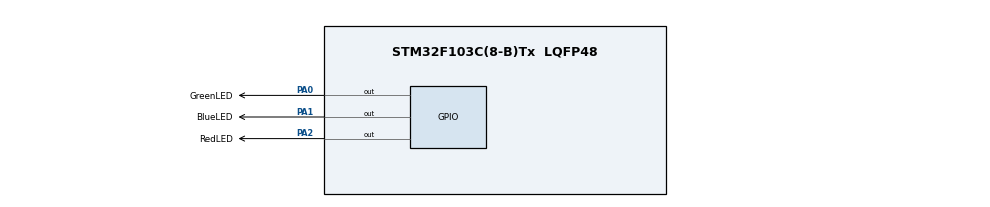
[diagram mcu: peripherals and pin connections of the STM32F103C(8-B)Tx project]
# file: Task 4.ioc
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FREERTOS.Tasks01=defaultTask,0,128,StartDefaultTask,Default,NULL,Dynamic,NULL,NULL;GreendLedFlash,-3,128,GreenLedTask,Default,NULL,Dynamic,NULL,NULL;RedLedFlash,0,128,RedLedTask,Default,NULL,Dynamic,NULL,NULL
FREERTOS.configUSE_NEWLIB_REENTRANT=1
Mcu.Family=STM32F1
Mcu.Name=STM32F103C(8-B)Tx
Mcu.Package=LQFP48
NVIC.PriorityGroup=NVIC_PRIORITYGROUP_4
NVIC.TIM4_IRQn=true\:15\:0\:false\:false\:true\:false\:false\:true\:true
NVIC.TimeBase=TIM4_IRQn
NVIC.TimeBaseIP=TIM4
PA0-WKUP.GPIO_Label=GreenLED
PA0-WKUP.Signal=GPIO_Output
PA1.GPIO_Label=BlueLED
PA1.Signal=GPIO_Output
PA13.Mode=Serial_Wire
PA13.Signal=SYS_JTMS-SWDIO
PA14.Mode=Serial_Wire
PA14.Signal=SYS_JTCK-SWCLK
PA2.GPIO_Label=RedLED
PA2.Signal=GPIO_Output
ProjectManager.HeapSize=0x200
ProjectManager.StackSize=0x400
ProjectManager.TargetToolchain=STM32CubeIDE
RCC.APB1Freq_Value=8000000
RCC.APB2Freq_Value=8000000
VP_FREERTOS_VS_CMSIS_V1.Mode=CMSIS_V1
VP_SYS_VS_tim4.Mode=TIM4
board=custom

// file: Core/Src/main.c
/* USER CODE BEGIN Header */
/**
  ******************************************************************************
  * @file           : main.c
  * @brief          : Main program body
  ******************************************************************************
  * @attention
  *
  * Copyright (c) 2024 STMicroelectronics.
  * All rights reserved.
  *
  * This software is licensed under terms that can be found in the LICENSE file
  * in the root directory of this software component.
  * If no LICENSE file comes with this software, it is provided AS-IS.
  *
  ******************************************************************************
  */
/* USER CODE END Header */
#include "main.h"
#include "cmsis_os.h"

/* USER CODE BEGIN PM */
volatile uint8_t startFlag = 1;
/* USER CODE END PM */

osThreadId defaultTaskHandle;
osThreadId GreendLedFlashHandle;
osThreadId RedLedFlashHandle;

void SystemClock_Config(void);
static void MX_GPIO_Init(void);
void StartDefaultTask(void const * argument);
void GreenLedTask(void const * argument);
void RedLedTask(void const * argument);

int main(void)
{

  /* MCU Configuration--------------------------------------------------------*/

  /* Reset of all peripherals, Initializes the Flash interface and the Systick. */
  HAL_Init();

  /* Configure the system clock */
  SystemClock_Config();

  /* Initialize all configured peripherals */
  MX_GPIO_Init();

  /* Create the thread(s) */
  /* definition and creation of defaultTask */
  osThreadDef(defaultTask, StartDefaultTask, osPriorityNormal, 0, 128);
  defaultTaskHandle = osThreadCreate(osThread(defaultTask), NULL);

  /* definition and creation of GreendLedFlash */
  osThreadDef(GreendLedFlash, GreenLedTask, osPriorityIdle, 0, 128);
  GreendLedFlashHandle = osThreadCreate(osThread(GreendLedFlash), NULL);

  /* definition and creation of RedLedFlash */
  osThreadDef(RedLedFlash, RedLedTask, osPriorityNormal, 0, 128);
  RedLedFlashHandle = osThreadCreate(osThread(RedLedFlash), NULL);

  /* Start scheduler */
  osKernelStart();
  /* We should never get here as control is now taken by the scheduler */
  /* Infinite loop */
  while (1)
  {

  }
}

void SystemClock_Config(void)
{
  RCC_OscInitTypeDef RCC_OscInitStruct = {0};
  RCC_ClkInitTypeDef RCC_ClkInitStruct = {0};

  /** Initializes the RCC Oscillators according to the specified parameters
  * in the RCC_OscInitTypeDef structure.
  */
  RCC_OscInitStruct.OscillatorType = RCC_OSCILLATORTYPE_HSI;
  RCC_OscInitStruct.HSIState = RCC_HSI_ON;
  RCC_OscInitStruct.HSICalibrationValue = RCC_HSICALIBRATION_DEFAULT;
  RCC_OscInitStruct.PLL.PLLState = RCC_PLL_NONE;
  if (HAL_RCC_OscConfig(&RCC_OscInitStruct) != HAL_OK)
  {
    Error_Handler();
  }

  /** Initializes the CPU, AHB and APB buses clocks
  */
  RCC_ClkInitStruct.ClockType = RCC_CLOCKTYPE_HCLK|RCC_CLOCKTYPE_SYSCLK
                              |RCC_CLOCKTYPE_PCLK1|RCC_CLOCKTYPE_PCLK2;
  RCC_ClkInitStruct.SYSCLKSource = RCC_SYSCLKSOURCE_HSI;
  RCC_ClkInitStruct.AHBCLKDivider = RCC_SYSCLK_DIV1;
  RCC_ClkInitStruct.APB1CLKDivider = RCC_HCLK_DIV1;
  RCC_ClkInitStruct.APB2CLKDivider = RCC_HCLK_DIV1;

  if (HAL_RCC_ClockConfig(&RCC_ClkInitStruct, FLASH_LATENCY_0) != HAL_OK)
  {
    Error_Handler();
  }
}

static void MX_GPIO_Init(void)
{
  GPIO_InitTypeDef GPIO_InitStruct = {0};

  /* GPIO Ports Clock Enable */
  __HAL_RCC_GPIOA_CLK_ENABLE();

  /*Configure GPIO pin Output Level */
  HAL_GPIO_WritePin(GPIOA, GreenLED_Pin|BlueLED_Pin|RedLED_Pin, GPIO_PIN_RESET);

  /*Configure GPIO pins : GreenLED_Pin BlueLED_Pin RedLED_Pin */
  GPIO_InitStruct.Pin = GreenLED_Pin|BlueLED_Pin|RedLED_Pin;
  GPIO_InitStruct.Mode = GPIO_MODE_OUTPUT_PP;
  GPIO_InitStruct.Pull = GPIO_NOPULL;
  GPIO_InitStruct.Speed = GPIO_SPEED_FREQ_LOW;
  HAL_GPIO_Init(GPIOA, &GPIO_InitStruct);

}

/* USER CODE BEGIN 4 */
void accessSharedData(void)
{
  if (startFlag == 1)
  {
    startFlag = 0;
  }
  else
  {
    HAL_GPIO_WritePin(GPIOA, GPIO_PIN_1, GPIO_PIN_SET);
  }
  osDelay(500);

  startFlag = 1;
  HAL_GPIO_WritePin(GPIOA, GPIO_PIN_1, GPIO_PIN_RESET);

}

/* USER CODE END 4 */

void StartDefaultTask(void const * argument)
{
  for(;;)
  {
    osDelay(1);
  }
}

/* USER CODE BEGIN Header_GreenLedTask */
/* USER CODE END Header_GreenLsudo udevadm control --reload-rules
sudo udevadm trigger
 * edTask */
void GreenLedTask(void const * argument)
{
  /* USER CODE BEGIN GreenLedTask */
  /* Infinite loop */
	for(;;)
		  {
		    HAL_GPIO_WritePin(GPIOA, GPIO_PIN_0, GPIO_PIN_SET);

		    accessSharedData();

		    HAL_GPIO_WritePin(GPIOA, GPIO_PIN_0, GPIO_PIN_RESET);

		    osDelay(500);
		  }
  /* USER CODE END GreenLedTask */
}

void RedLedTask(void const * argument)
{
  /* USER CODE BEGIN RedLedTask */
  /* Infinite loop */
	for(;;)
		  {
		    HAL_GPIO_WritePin(GPIOA, GPIO_PIN_2, GPIO_PIN_SET);

		    accessSharedData();

		    HAL_GPIO_WritePin(GPIOA, GPIO_PIN_2, GPIO_PIN_RESET);

		    // Menunda selama 0.1 detik
		    osDelay(100);
		  }
  /* USER CODE END RedLedTask */
}

void HAL_TIM_PeriodElapsedCallback(TIM_HandleTypeDef *htim)
{
  if (htim->Instance == TIM4) {
    HAL_IncTick();
  }
}

void Error_Handler(void)
{
  __disable_irq();
  while (1)
  {
  }
}
